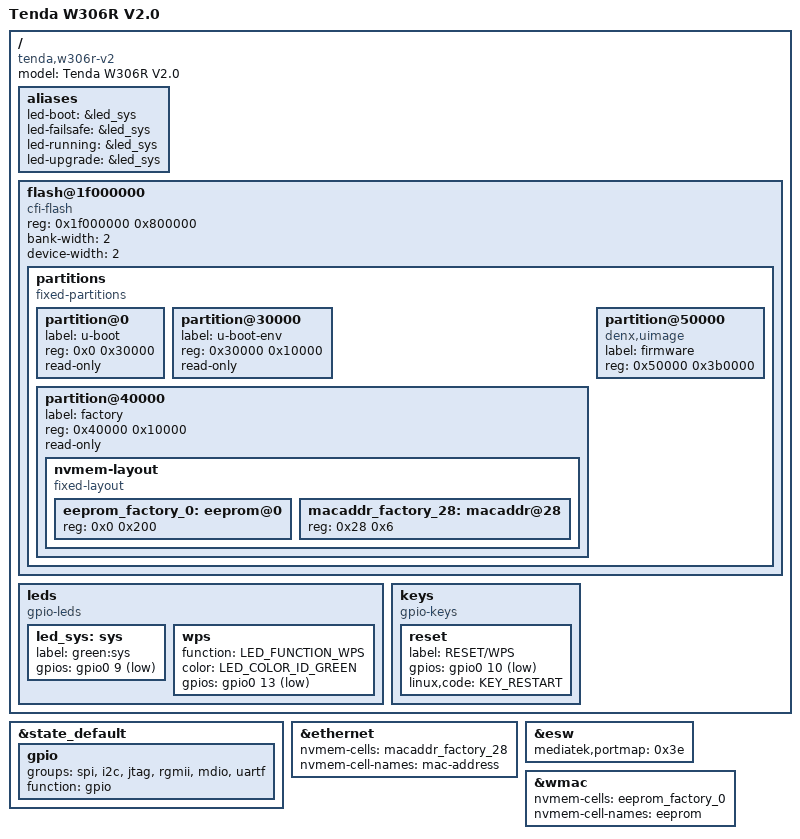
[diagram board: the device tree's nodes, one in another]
#include "rt3050.dtsi"

#include <dt-bindings/gpio/gpio.h>
#include <dt-bindings/input/input.h>
#include <dt-bindings/leds/common.h>

/ {
	compatible = "tenda,w306r-v2", "ralink,rt3052-soc";
	model = "Tenda W306R V2.0";

	aliases {
		led-boot = &led_sys;
		led-failsafe = &led_sys;
		led-running = &led_sys;
		led-upgrade = &led_sys;
	};

	flash@1f000000 {
		compatible = "cfi-flash";
		reg = <0x1f000000 0x800000>;
		bank-width = <2>;
		device-width = <2>;

		partitions {
			compatible = "fixed-partitions";
			#address-cells = <1>;
			#size-cells = <1>;

			partition@0 {
				label = "u-boot";
				reg = <0x0 0x30000>;
				read-only;
			};

			partition@30000 {
				label = "u-boot-env";
				reg = <0x30000 0x10000>;
				read-only;
			};

			partition@40000 {
				label = "factory";
				reg = <0x40000 0x10000>;
				read-only;

				nvmem-layout {
					compatible = "fixed-layout";
					#address-cells = <1>;
					#size-cells = <1>;

					eeprom_factory_0: eeprom@0 {
						reg = <0x0 0x200>;
					};

					macaddr_factory_28: macaddr@28 {
						reg = <0x28 0x6>;
					};
				};
			};

			partition@50000 {
				compatible = "denx,uimage";
				label = "firmware";
				reg = <0x50000 0x3b0000>;
			};
		};
	};

	leds {
		compatible = "gpio-leds";

		led_sys: sys {
			label = "green:sys";
			gpios = <&gpio0 9 GPIO_ACTIVE_LOW>;
		};

		wps {
			function = LED_FUNCTION_WPS;
			color = <LED_COLOR_ID_GREEN>;
			gpios = <&gpio0 13 GPIO_ACTIVE_LOW>;
		};
	};

	keys {
		compatible = "gpio-keys";

		reset {
			label = "RESET/WPS";
			gpios = <&gpio0 10 GPIO_ACTIVE_LOW>;
			linux,code = <KEY_RESTART>;
		};
	};
};

&state_default {
	gpio {
		groups = "spi", "i2c", "jtag", "rgmii", "mdio", "uartf";
		function = "gpio";
	};
};

&ethernet {
	nvmem-cells = <&macaddr_factory_28>;
	nvmem-cell-names = "mac-address";
};

&esw {
	mediatek,portmap = <0x3e>;
};

&wmac {
	nvmem-cells = <&eeprom_factory_0>;
	nvmem-cell-names = "eeprom";
};
